# nrf9230_engb_celldsp register map
Vendor: Nordic Semiconductor; Series: nRF92; File version: 1
Registers are 32-bit, read-write, reset 0x0 unless marked. A register's access mark holds for its fields unless they carry their own. Offsets are from the block's base; [hi:lo] are bit positions; {n}, {i} and the like mark numbered series; 'fields as' and 'values as' point back to an identical list.

## VITERBI
Base 0x4500D000
0x00 TASKS_START wo — Viterbi Decoder Task Trigger. Same function as taskTrigStartLteViterbiDec input signal. Readable if the parameter SELECT_TASK_REGISTERS is 1. Cleared when the MCU writes a 0 to it.
  [0] TASKS_START
    1=Trigger task
0x04 TASKS_STOP wo — Viterbi Decoder Task Trigger. Same function as taskTrigStopLteViterbiDec input signal. Readable if the parameter SELECT_TASK_REGISTERS is 1. Cleared when the MCU writes a 0 to it.
  [0] TASKS_STOP
    1=Trigger task
0x100 EVENTS_DONE — Viterbi Decoder Event register. Indicates that Viterbi decoding is done. Set when signal eventLteViterbiDecDone is high, or when the MCU writes 1 to this address and SELECT_EVENT_TRIGGERS is 1. Cleared when the MCU writes a 0 to it.
  [0] EVENTS_DONE
    0=NotGenerated (Event not generated); 1=Generated (Event generated)
0x104 EVENTS_DMADONE — Viterbi Decoder Event register. Indicates that reading of softbits is done. Set when signal eventLteViterbiDecDmaDone is high, or when the MCU writes 1 to this address and SELECT_EVENT_TRIGGERS is 1. Cleared when the MCU writes a 0 to it.
  [0] EVENTS_DMADONE
    values as EVENTS_DONE.EVENTS_DONE
0x108 EVENTS_STOPPED — Viterbi Decoder Event register. Indicates that module is stopped using task lteViterbiDecTaskTrigStop when module is reading softbits or decoding. Set when signal eventLteViterbiDecStopped is high, or when the MCU writes 1 to this address and SELECT_EVENT_TRIGGERS is 1. Cleared when the MCU writes a 0 to it.
  [0] EVENTS_STOPPED
    values as EVENTS_DONE.EVENTS_DONE
0x10C EVENTS_AHBBUSERROR — Viterbi Decoder Event register. Indicates that Ahb Bus access was terminated using HResp response. Set when eventLteViterbiDecAhbBusError is high, or when the MCU writes 1 to this address and SELECT_EVENT_TRIGGERS is 1. Cleared when the MCU writes a 0 to it.
  [0] EVENTS_AHBBUSERROR
    values as EVENTS_DONE.EVENTS_DONE
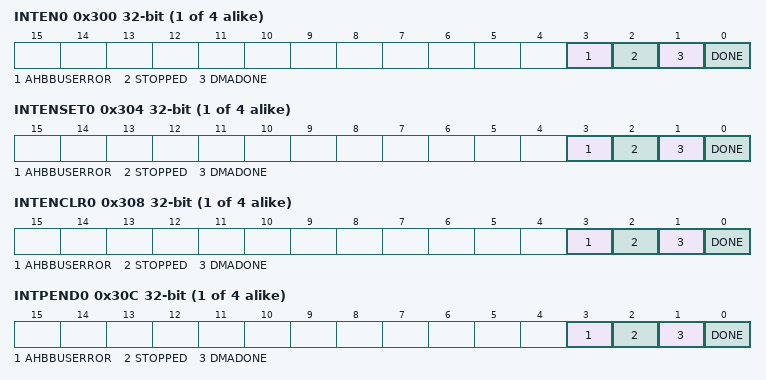
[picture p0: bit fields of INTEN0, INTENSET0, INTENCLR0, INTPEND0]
{0x300+0x10*i} INTEN{i} (i=0..3) — Enable or disable interrupt
  [all] fields
    0=Disabled; 1=Enabled
  [3] AHBBUSERROR — Enable or disable interrupt for event AHBBUSERROR
  [2] STOPPED — Enable or disable interrupt for event STOPPED
  [1] DMADONE — Enable or disable interrupt for event DMADONE
  [0] DONE — Enable or disable interrupt for event DONE
{0x304+0x10*i} INTENSET{i} (i=0..3) — Enable interrupt
  [all] fields
    on read: 0=Disabled (Read: Disabled); 1=Enabled (Read: Enabled) | on write: 1=Set (Enable)
  [3] AHBBUSERROR — Write '1' to enable interrupt for event AHBBUSERROR
  [2] STOPPED — Write '1' to enable interrupt for event STOPPED
  [1] DMADONE — Write '1' to enable interrupt for event DMADONE
  [0] DONE — Write '1' to enable interrupt for event DONE
{0x308+0x10*i} INTENCLR{i} (i=0..3) — Disable interrupt
  [all] fields
    on read: 0=Disabled (Read: Disabled); 1=Enabled (Read: Enabled) | on write: 1=Clear (Disable)
  [3] AHBBUSERROR — Write '1' to disable interrupt for event AHBBUSERROR
  [2] STOPPED — Write '1' to disable interrupt for event STOPPED
  [1] DMADONE — Write '1' to disable interrupt for event DMADONE
  [0] DONE — Write '1' to disable interrupt for event DONE
{0x30C+0x10*i} INTPEND{i} ro (i=0..3) — Pending interrupts
  [all] fields
    on read: 0=NotPending (Read: Not pending); 1=Pending (Read: Pending)
  [3] AHBBUSERROR — Read pending status of interrupt for event AHBBUSERROR
  [2] STOPPED — Read pending status of interrupt for event STOPPED
  [1] DMADONE — Read pending status of interrupt for event DMADONE
  [0] DONE — Read pending status of interrupt for event DONE
0x500 ENABLE — Enable LteViterbiDec module
  [0] ENABLE — Enable LteViterbiDec module. This must be enabled before starting the decoder and disabled when the results are no longer needed.
    0=Disabled; 1=Enabled
0x504 INITDEC reset 0x1 — The register defines how many training cycles are run to calculate the path metrics before the output bits are decoded out
  [3:0] INITDEC — Number training cycles of path metrics over the 64-bit window, the range is 1 to 15. Assumed value is 3.
0x508 MAXITR reset 0x1 — The register defines the maximum number of iteration cycles to calculate the output bits
  [2:0] MAXITR — Maximum number of data decoding rounds over a data frame, the range is 1 to 7. Assumed value is 3.
0x50C NBIT reset 0x6 — The register defines the number of output bits to be decoded
  [6:0] NBIT — Number of output bits to be decoded, the range is from 6 to 64
0x510 ADDRESSSOFTBITS — The register defines the address of the soft bits, which are read in into the decoder as input data
  [31:0] ADDRESSSOFTBITS — Address of the soft bits, which are read in into the decoder as input data
0x514 CRCPOLY — The register defines the CRC polynomial
  [16:0] CRCPOLY — Crc polynomial. Aligned to the MSB of bit 16 if degree of the polynom is less than 16.
0x518 CRCONOFF — The register enables the CRC unit
  [0] CRCONOFF — This bit enables the CRC unit
    0=Disabled; 1=Enabled
0x51C POLY0 — The 1st code polynomial
  [6:0] POLY0
0x520 POLY1 — The 2nd code polynomial
  [6:0] POLY1
0x524 POLY2 — The 3rd code polynomial
  [6:0] POLY2
0x528 SOFTBITOFFSET — The register defines initial offset to an internal softBit data input buffer, points to a triplet of soft bits
  [6:0] SOFTBITOFFSET — Initial offset to an internal softBit data input buffer, points to a triplet of soft bits. SW is responsible for computing a correct value for the offset, the range 0...(nBit-1): k = (initDec-1)*64 k = k mod nBit; if (k != 0) k=nBit-k; softBitOffset = k;
0x52C PTRDECBITREG — The register defines initial pointer value to the circular buffer decBitReg
  [5:0] PTRDECBITREG — Initial pointer value to the circular buffer decBitReg. Assumed value is 0.
0x530 SOFTBITOFFSETOUT ro — Status register indicating offset to softBit-input buffer. Points to a triplet of soft bits.
  [6:0] SOFTBITOFFSETOUT
0x534 PTRDECBITREGOUT ro — Status register indicating pointer to the circular buffer decBitReg
  [5:0] PTRDECBITREGOUT
0x538 ABSSUMSOFTBITS ro — Status register indicating sum of absolute values of soft bits
  [15:0] ABSSUMSOFTBITS — The sum of absolute values of soft bits, unsigned type. The maximum value is 24576 (128*3*64).
0x53C CUMULATIVEPM ro — Status register indicating cumulative path metric of the best path
  [15:0] CUMULATIVEPM — Cumulative path metric of the best path, unsigned type. The value is less or equal to 24576.
0x540 MAXPATHMETRIC ro — Status register indicating the difference of the maximum path metric and the zero path metric
  [11:0] MAXPATHMETRIC — The difference of the maximum path metric and the zero path metric
0x544 STATEMAXPM ro — Status register indicating the state index of the maximum path metric
  [5:0] STATEMAXPM — The state index of the maximum path metric
0x548 FIRSTSIXBITSMS ro — Status register indicating the first six data bits corresponding the state of the maximum path metric
  [5:0] FIRSTSIXBITSMS — The first six data bits corresponding the state of the maximum path metric
0x54C CRCBITOUT ro — Status register indicating the CRC-bits. Evaluated over all decoded bits.
  [15:0] CRCBITOUT — CRC-bits, evaluated over all decoded bits. Result 0x0000 means CRC passed (if not masked). Ordering: crc8 .. crc15, crc0 .. crc7
0x550 OUTBIT1 ro — Status register indicating the decoded bits 0 to 31
  [31:0] OUTBIT1 — Decoded bits 0 to 31 to output, the number of the decoded output bits is nBit. Ordering: a0 .. a7, a8 .. a15, a16 .. a23, a24 .. a31
0x554 OUTBIT2 ro — Status register indicating the decoded bits 32 to 63
  [31:0] OUTBIT2 — Decoded bits 32 to 63 to output, the number of the decoded output bits is nBit. Ordering: a32 .. a39, a40 .. a47, a48 .. a55, a56 .. a63
0x558 OUTBIT3 ro — Status register indicating the decoded bits 64 to 95
  [31:0] OUTBIT2 — Decoded bits 64 to 95 to output, the number of the decoded output bits is nBit. Ordering: a64 .. a71, a72 .. a79, a80 .. a87, a88 .. a95
0x55C PMREG — Status register interface for reading out 64 pcs. path metrics
  [11:0] PMREG — Reading this register produces 64 pcs. path metrics, 12-bit wide each. Location 0 is read first (pmReg[0][11:0]). Read pointer is reinitialized by a write operation to this register.
0x560 DECBITREG — Status register interface for reading out 64 bit vectors of 64 bits from DecBitReg
  [31:0] DECBITREG — Reading this register produces 64 bit vectors of 64 bits. Bits [31:0] are read first from location 0. The next read produces bits [63:32] from location 0. Read pointer is reinitialized by a write operation to this register.
0x564 TEST1 ro — Status register like the lteViterbiDecCrcBitOut, but using an alternative bit order
  [15:0] TEST1 — Contents of the lteViterbiDecCrcBitOut, but using an alternative bit order. Ordering: crc15 ... crc0
0x568 TEST2 ro — Status register like the lteViterbiDecOutBit1, but using an alternative bit order
  [31:0] TEST2 — Contents of the lteViterbiDecOutBit1, but using an alternative bit order. Ordering: a31 ... a0
0x56C TEST3 ro — Status register like the lteViterbiDecOutBit2, but using an alternative bit order
  [31:0] TEST3 — Contents of the lteViterbiDecOutBit2, but using an alternative bit order. Ordering: a63 ... a32
0x570 TEST4 ro — Status register like the lteViterbiDecOutBit3, but using an alternative bit order
  [31:0] TEST3 — Contents of the lteViterbiDecOutBit3, but using an alternative bit order. Ordering: a95 ... a64
